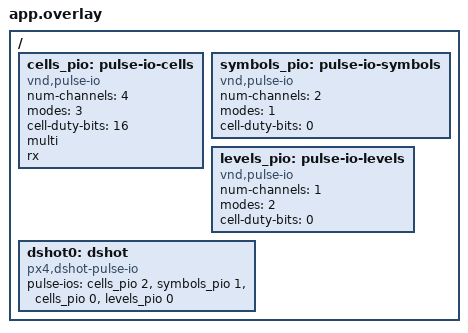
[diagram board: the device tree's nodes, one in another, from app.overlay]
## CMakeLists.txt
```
############################################################################
#
#   Copyright (c) 2026 PX4 Development Team. All rights reserved.
#
# Redistribution and use in source and binary forms, with or without
# modification, are permitted provided that the following conditions
# are met:
#
# 1. Redistributions of source code must retain the above copyright
#    notice, this list of conditions and the following disclaimer.
# 2. Redistributions in binary form must reproduce the above copyright
#    notice, this list of conditions and the following disclaimer in
#    the documentation and/or other materials provided with the
#    distribution.
# 3. Neither the name PX4 nor the names of its contributors may be
#    used to endorse or promote products derived from this software
#    without specific prior written permission.
#
# THIS SOFTWARE IS PROVIDED BY THE COPYRIGHT HOLDERS AND CONTRIBUTORS
# "AS IS" AND ANY EXPRESS OR IMPLIED WARRANTIES, INCLUDING, BUT NOT
# LIMITED TO, THE IMPLIED WARRANTIES OF MERCHANTABILITY AND FITNESS
# FOR A PARTICULAR PURPOSE ARE DISCLAIMED. IN NO EVENT SHALL THE
# COPYRIGHT OWNER OR CONTRIBUTORS BE LIABLE FOR ANY DIRECT, INDIRECT,
# INCIDENTAL, SPECIAL, EXEMPLARY, OR CONSEQUENTIAL DAMAGES (INCLUDING,
# BUT NOT LIMITED TO, PROCUREMENT OF SUBSTITUTE GOODS OR SERVICES; LOSS
# OF USE, DATA, OR PROFITS; OR BUSINESS INTERRUPTION) HOWEVER CAUSED
# AND ON ANY THEORY OF LIABILITY, WHETHER IN CONTRACT, STRICT
# LIABILITY, OR TORT (INCLUDING NEGLIGENCE OR OTHERWISE) ARISING IN
# ANY WAY OUT OF THE USE OF THIS SOFTWARE, EVEN IF ADVISED OF THE
# POSSIBILITY OF SUCH DAMAGE.
#
############################################################################

cmake_minimum_required(VERSION 3.20.0)

find_package(Zephyr REQUIRED HINTS $ENV{ZEPHYR_BASE})
project(px4_dshot_pulse_io_test)

target_sources(app PRIVATE
	src/fake_pulse_io.c
	src/main.c
)
```

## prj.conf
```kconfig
CONFIG_ZTEST=y
CONFIG_PX4=y
```

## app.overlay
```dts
/ {
	/* cells with a duty cycle, whose channels start together, as an STM32 timer */
	cells_pio: pulse-io-cells {
		compatible = "vnd,pulse-io";
		#pulse-io-cells = <1>;
		num-channels = <4>;
		modes = <3>;
		cell-duty-bits = <16>;
		multi;
		rx;
	};

	/* symbols only, as the RMT of the ESP32 */
	symbols_pio: pulse-io-symbols {
		compatible = "vnd,pulse-io";
		#pulse-io-cells = <1>;
		num-channels = <2>;
		modes = <1>;
		cell-duty-bits = <0>;
	};

	/* cells without a duty cycle, which can't send DShot */
	levels_pio: pulse-io-levels {
		compatible = "vnd,pulse-io";
		#pulse-io-cells = <1>;
		num-channels = <1>;
		modes = <2>;
		cell-duty-bits = <0>;
	};

	/* channels in another order than those of the controllers */
	dshot0: dshot {
		compatible = "px4,dshot-pulse-io";
		#dshot-cells = <1>;
		pulse-ios = <&cells_pio 2>, <&symbols_pio 1>, <&cells_pio 0>, <&levels_pio 0>;
	};
};
```

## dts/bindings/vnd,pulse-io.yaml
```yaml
description: |
  pulse_io controller of the PX4 DShot pulse_io test, which records the
  configuration of its channels and what they send

compatible: "vnd,pulse-io"

include: pulse-io-controller.yaml

properties:
  num-channels:
    type: int
    required: true
  modes:
    type: int
    required: true
    description: pulse_io_mode bitmask of the capabilities
  cell-duty-bits:
    type: int
    required: true
  multi:
    type: boolean
    description: the channels can start together (tx_sync_multi_channel)
  rx:
    type: boolean
    description: the channels receive the reply set by the test after a transmit, through RTIO
```

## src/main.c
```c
/****************************************************************************
 *
 *   Copyright (c) 2026 PX4 Development Team. All rights reserved.
 *
 * Redistribution and use in source and binary forms, with or without
 * modification, are permitted provided that the following conditions
 * are met:
 *
 * 1. Redistributions of source code must retain the above copyright
 *    notice, this list of conditions and the following disclaimer.
 * 2. Redistributions in binary form must reproduce the above copyright
 *    notice, this list of conditions and the following disclaimer in
 *    the documentation and/or other materials provided with the
 *    distribution.
 * 3. Neither the name PX4 nor the names of its contributors may be
 *    used to endorse or promote products derived from this software
 *    without specific prior written permission.
 *
 * THIS SOFTWARE IS PROVIDED BY THE COPYRIGHT HOLDERS AND CONTRIBUTORS
 * "AS IS" AND ANY EXPRESS OR IMPLIED WARRANTIES, INCLUDING, BUT NOT
 * LIMITED TO, THE IMPLIED WARRANTIES OF MERCHANTABILITY AND FITNESS
 * FOR A PARTICULAR PURPOSE ARE DISCLAIMED. IN NO EVENT SHALL THE
 * COPYRIGHT OWNER OR CONTRIBUTORS BE LIABLE FOR ANY DIRECT, INDIRECT,
 * INCIDENTAL, SPECIAL, EXEMPLARY, OR CONSEQUENTIAL DAMAGES (INCLUDING,
 * BUT NOT LIMITED TO, PROCUREMENT OF SUBSTITUTE GOODS OR SERVICES; LOSS
 * OF USE, DATA, OR PROFITS; OR BUSINESS INTERRUPTION) HOWEVER CAUSED
 * AND ON ANY THEORY OF LIABILITY, WHETHER IN CONTRACT, STRICT
 * LIABILITY, OR TORT (INCLUDING NEGLIGENCE OR OTHERWISE) ARISING IN
 * ANY WAY OUT OF THE USE OF THIS SOFTWARE, EVEN IF ADVISED OF THE
 * POSSIBILITY OF SUCH DAMAGE.
 *
 ****************************************************************************/

/*
 * DShot device on pulse_io channels (px4,dshot-pulse-io), on pulse_io controllers of the test: the
 * configuration of the channels for each bit rate, the cells and symbols of the frames, the channels of a
 * controller that start together and the others, the inverted frames of bidirectional channels and the
 * replies received after them, and the errors.
 */

#include "fake_pulse_io.h"

#include <px4_dshot.h>

#include <errno.h>

#include <zephyr/device.h>
#include <zephyr/ztest.h>

static const struct device *const dshot = DEVICE_DT_GET(DT_NODELABEL(dshot0));
static const struct device *const cells_pio = DEVICE_DT_GET(DT_NODELABEL(cells_pio));
static const struct device *const symbols_pio = DEVICE_DT_GET(DT_NODELABEL(symbols_pio));
static const struct device *const levels_pio = DEVICE_DT_GET(DT_NODELABEL(levels_pio));

/* the pulse_io channels of the DShot channels, see app.overlay */
#define CH0 fake_pio_channel(cells_pio, 2)
#define CH1 fake_pio_channel(symbols_pio, 1)
#define CH2 fake_pio_channel(cells_pio, 0)
#define CH3 fake_pio_channel(levels_pio, 0)

/* ticks of a bit, high time of a 1 and of a 0 */
#define BIT_TICKS  40
#define ONE_TICKS  30
#define ZERO_TICKS 15

static void reset(void *fixture)
{
	ARG_UNUSED(fixture);

	zassert_ok(px4_dshot_configure(dshot, 0, 0, 600000));
	fake_pio_clear();
}

ZTEST_SUITE(dshot_pulse_io, NULL, NULL, reset, NULL, NULL);

static void check_channel_config(const struct fake_pio_channel *ch, enum pulse_io_mode mode, uint32_t bit_rate)
{
	zassert_true(ch->reserved);
	zassert_true(ch->configured);
	zassert_equal(ch->cfg.mode, mode);
	zassert_equal(ch->cfg.dir, PULSE_IO_DIR_TX);
	zassert_equal(ch->cfg.resolution_hz, bit_rate * BIT_TICKS);
	zassert_false(ch->cfg.idle_high);

	if (mode == PULSE_IO_MODE_CELL) {
		zassert_equal(ch->cfg.cell_period_ticks, BIT_TICKS);
	}
}

ZTEST(dshot_pulse_io, test_configure)
{
	zassert_ok(px4_dshot_configure(dshot, BIT(0) | BIT(1) | BIT(2), 0, 600000));

	check_channel_config(CH0, PULSE_IO_MODE_CELL, 600000);
	check_channel_config(CH1, PULSE_IO_MODE_SYMBOL, 600000);
	check_channel_config(CH2, PULSE_IO_MODE_CELL, 600000);

	/* the channels that aren't DShot channels, or aren't configured, are left alone */
	zassert_false(fake_pio_channel(cells_pio, 1)->reserved);
	zassert_false(fake_pio_channel(cells_pio, 3)->reserved);
	zassert_false(fake_pio_channel(symbols_pio, 0)->reserved);
	zassert_false(CH3->reserved);
}

ZTEST(dshot_pulse_io, test_bit_rates)
{
	zassert_ok(px4_dshot_configure(dshot, BIT(0) | BIT(1), 0, 150000));
	check_channel_config(CH0, PULSE_IO_MODE_CELL, 150000);
	check_channel_config(CH1, PULSE_IO_MODE_SYMBOL, 150000);

	zassert_ok(px4_dshot_configure(dshot, BIT(0) | BIT(1), 0, 300000));
	check_channel_config(CH0, PULSE_IO_MODE_CELL, 300000);
	check_channel_config(CH1, PULSE_IO_MODE_SYMBOL, 300000);
}

ZTEST(dshot_pulse_io, test_reconfigure)
{
	zassert_ok(px4_dshot_configure(dshot, BIT(0) | BIT(2), 0, 600000));

	/* in place of the previous configuration */
	zassert_ok(px4_dshot_configure(dshot, BIT(0), 0, 600000));
	check_channel_config(CH0, PULSE_IO_MODE_CELL, 600000);
	zassert_false(CH2->reserved);

	zassert_equal(px4_dshot_send(dshot, BIT(2), (const uint16_t[3]) {0}), -EINVAL);
	zassert_equal(CH2->transmits, 0);
}

ZTEST(dshot_pulse_io, test_configure_errors)
{
	zassert_ok(px4_dshot_configure(dshot, BIT(0), 0, 600000));

	/* a bidirectional channel on a controller that doesn't receive */
	zassert_equal(px4_dshot_configure(dshot, BIT(1), BIT(1), 600000), -EINVAL);
	zassert_ok(px4_dshot_configure(dshot, BIT(0), 0, 600000));

	zassert_equal(px4_dshot_configure(dshot, BIT(0), 0, 400000), -EINVAL);
	zassert_equal(px4_dshot_configure(dshot, BIT(4), 0, 600000), -EINVAL);

	/* cells without a duty cycle, which leaves no channel configured */
	zassert_ok(px4_dshot_configure(dshot, BIT(0), 0, 600000));
	zassert_equal(px4_dshot_configure(dshot, BIT(0) | BIT(3), 0, 600000), -EINVAL);
	zassert_false(CH0->reserved);
	zassert_false(CH3->reserved);
	zassert_equal(px4_dshot_send(dshot, BIT(0), (const uint16_t[1]) {0}), -EINVAL);
}

ZTEST(dshot_pulse_io, test_frames)
{
	/* bits 1010 0101 1100 0011, the most significant first */
	const uint16_t frame = 0xa5c3;
	const uint16_t frames[3] = {frame, frame, frame};

	zassert_ok(px4_dshot_configure(dshot, BIT(0) | BIT(1) | BIT(2), 0, 600000));
	zassert_ok(px4_dshot_send(dshot, BIT(0) | BIT(1) | BIT(2), frames));

	/* 16 cells and an idle cell */
	for (int c = 0; c < 2; c++) {
		const struct fake_pio_channel *ch = (c == 0) ? CH0 : CH2;

		zassert_equal(ch->transmits, 1);
		zassert_equal(ch->count, 17);

		for (int i = 0; i < 16; i++) {
			const bool one = (frame & BIT(15 - i)) != 0;

			zassert_equal(ch->cells[i].duty, one ? ONE_TICKS : ZERO_TICKS, "cell %d", i);
		}

		zassert_equal(ch->cells[16].duty, 0);
	}

	/* a high and a low symbol for each bit */
	zassert_equal(CH1->transmits, 1);
	zassert_equal(CH1->count, 32);

	for (int i = 0; i < 16; i++) {
		const bool one = (frame & BIT(15 - i)) != 0;

		zassert_equal(CH1->symbols[2 * i].level, 1);
		zassert_equal(CH1->symbols[2 * i].duration, one ? ONE_TICKS : ZERO_TICKS, "bit %d", i);
		zassert_equal(CH1->symbols[2 * i + 1].level, 0);
		zassert_equal(CH1->symbols[2 * i + 1].duration, one ? BIT_TICKS - ONE_TICKS : BIT_TICKS - ZERO_TICKS);
	}
}

ZTEST(dshot_pulse_io, test_channels)
{
	const uint16_t frames[3] = {0x0001, 0x0002, 0x0004};

	zassert_ok(px4_dshot_configure(dshot, BIT(0) | BIT(1) | BIT(2), 0, 600000));

	/* the given channels, each with its frame, which start together on the same controller */
	zassert_ok(px4_dshot_send(dshot, BIT(0) | BIT(2), frames));
	zassert_equal(CH0->transmits, 1);
	zassert_equal(CH1->transmits, 0);
	zassert_equal(CH2->transmits, 1);
	zassert_equal(CH0->cells[15].duty, ONE_TICKS);
	zassert_equal(CH2->cells[13].duty, ONE_TICKS);
	zassert_equal(CH2->cells[15].duty, ZERO_TICKS);
	zassert_true(CH0->multi);
	zassert_true(CH2->multi);
	zassert_equal(CH0->sequence, CH2->sequence);

	/* the channel of the other controller after them */
	zassert_ok(px4_dshot_send(dshot, BIT(0) | BIT(1) | BIT(2), frames));
	zassert_equal(CH0->sequence, CH2->sequence);
	zassert_true(CH0->sequence < CH1->sequence);
	zassert_false(CH1->multi);

	/* a single channel of a controller */
	zassert_ok(px4_dshot_send(dshot, BIT(2), frames));
	zassert_false(CH2->multi);
	zassert_equal(CH2->transmits, 3);
}

ZTEST(dshot_pulse_io, test_transmit_error)
{
	const uint16_t frames[3] = {0};

	zassert_ok(px4_dshot_configure(dshot, BIT(0) | BIT(1) | BIT(2), 0, 600000));

	/* the other channels still send */
	CH1->transmit_error = -EIO;
	zassert_equal(px4_dshot_send(dshot, BIT(0) | BIT(1) | BIT(2), frames), -EIO);
	zassert_equal(CH0->transmits, 1);
	zassert_equal(CH2->transmits, 1);

	/* also those that start together with the failing one */
	CH1->transmit_error = 0;
	CH2->transmit_error = -EIO;
	zassert_equal(px4_dshot_send(dshot, BIT(0) | BIT(1) | BIT(2), frames), -EIO);
	zassert_equal(CH0->transmits, 2);
	zassert_equal(CH1->transmits, 1);
}

ZTEST(dshot_pulse_io, test_no_reply)
{
	uint32_t reply;

	zassert_ok(px4_dshot_configure(dshot, BIT(0), 0, 600000));
	zassert_ok(px4_dshot_send(dshot, BIT(0), (const uint16_t[1]) {0}));
	zassert_equal(px4_dshot_get_reply(dshot, 0, &reply), -ENODATA);
}

/* ticks of a bit of the reply, at 5/4 of the bit rate */
#define REPLY_BIT_TICKS 32

/* the symbols of a reply 30 us after the frame: the start bit, then 20 bits as line levels, the first in bit 19 */
static size_t make_reply(struct pulse_symbol *symbols, uint32_t bits)
{
	size_t n = 0;

	symbols[n++] = (struct pulse_symbol) {.duration = 720, .level = 1};
	symbols[n++] = (struct pulse_symbol) {.duration = REPLY_BIT_TICKS, .level = 0};

	for (int i = 19; i >= 0; i--) {
		const uint32_t level = (bits >> i) & 1;

		if (symbols[n - 1].level == level) {
			symbols[n - 1].duration += REPLY_BIT_TICKS;

		} else {
			symbols[n++] = (struct pulse_symbol) {.duration = REPLY_BIT_TICKS, .level = level};
		}
	}

	/* the line idles high after the reply */
	if (symbols[n - 1].level == 1) {
		symbols[n - 1].duration += 1440;

	} else {
		symbols[n++] = (struct pulse_symbol) {.duration = 1440, .level = 1};
	}

	return n;
}

ZTEST(dshot_pulse_io, test_bidirectional_configure)
{
	zassert_ok(px4_dshot_configure(dshot, BIT(0) | BIT(2), BIT(0), 600000));

	/* half duplex, idling high, with a receive that ends 60 us after the last edge */
	zassert_equal(CH0->cfg.dir, PULSE_IO_DIR_TX_RX);
	zassert_true(CH0->cfg.idle_high);
	zassert_equal(CH0->cfg.rx_idle_threshold_ticks, 24 * 60);
	zassert_equal(CH2->cfg.dir, PULSE_IO_DIR_TX);
	zassert_false(CH2->cfg.idle_high);

	/* the line rests low for the 20 ms that take an AM32 ESC out of its bootloader before it idles high */
	zassert_true(CH0->low_before_high_ms >= 20, "low for %lld ms", CH0->low_before_high_ms);

	/* a controller that doesn't receive, and a bidirectional channel that isn't configured */
	zassert_equal(px4_dshot_configure(dshot, BIT(1), BIT(1), 600000), -EINVAL);
	zassert_equal(px4_dshot_configure(dshot, BIT(0), BIT(2), 600000), -EINVAL);
}

ZTEST(dshot_pulse_io, test_bidirectional_frame)
{
	/* bits 1010 0101 1100 0011 */
	const uint16_t frame = 0xa5c3;
	uint32_t reply;

	zassert_equal(px4_dshot_get_reply(dshot, 0, &reply), -ENODATA);

	zassert_ok(px4_dshot_configure(dshot, BIT(0), BIT(0), 600000));
	zassert_ok(px4_dshot_send(dshot, BIT(0), &frame));

	/* inverted: the line is low for 3/4 of a 1 and 3/8 of a 0, then idles high, sent without the others */
	zassert_equal(CH0->transmits, 1);
	zassert_false(CH0->multi);
	zassert_equal(CH0->count, 17);

	for (int i = 0; i < 16; i++) {
		const bool one = (frame & BIT(15 - i)) != 0;

		zassert_equal(CH0->cells[i].duty, one ? BIT_TICKS - ONE_TICKS : BIT_TICKS - ZERO_TICKS, "cell %d", i);
	}

	zassert_equal(CH0->cells[16].duty, BIT_TICKS);

	/* the line stays high: no reply */
	zassert_equal(CH0->receives, 1);
	zassert_equal(px4_dshot_get_reply(dshot, 0, &reply), -ENODATA);
}

ZTEST(dshot_pulse_io, test_bidirectional_reply)
{
	const uint32_t bits[] = {0xa5c3f, 0x00001, 0xfffff, 0x55555};
	uint32_t reply;

	zassert_ok(px4_dshot_configure(dshot, BIT(0) | BIT(2), BIT(0) | BIT(2), 600000));

	for (size_t i = 0; i < ARRAY_SIZE(bits); i++) {
		CH0->reply_count = make_reply(CH0->reply, bits[i]);
		CH2->reply_count = make_reply(CH2->reply, bits[i] ^ 0xfffff);

		zassert_ok(px4_dshot_send(dshot, BIT(0) | BIT(2), (const uint16_t[3]) {0}));

		zassert_ok(px4_dshot_get_reply(dshot, 0, &reply));
		zassert_equal(reply, bits[i], "reply 0x%05x instead of 0x%05x", reply, bits[i]);
		zassert_ok(px4_dshot_get_reply(dshot, 2, &reply));
		zassert_equal(reply, bits[i] ^ 0xfffff);

		/* returned once */
		zassert_equal(px4_dshot_get_reply(dshot, 0, &reply), -ENODATA);
	}
}
```

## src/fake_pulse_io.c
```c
/****************************************************************************
 *
 *   Copyright (c) 2026 PX4 Development Team. All rights reserved.
 *
 * Redistribution and use in source and binary forms, with or without
 * modification, are permitted provided that the following conditions
 * are met:
 *
 * 1. Redistributions of source code must retain the above copyright
 *    notice, this list of conditions and the following disclaimer.
 * 2. Redistributions in binary form must reproduce the above copyright
 *    notice, this list of conditions and the following disclaimer in
 *    the documentation and/or other materials provided with the
 *    distribution.
 * 3. Neither the name PX4 nor the names of its contributors may be
 *    used to endorse or promote products derived from this software
 *    without specific prior written permission.
 *
 * THIS SOFTWARE IS PROVIDED BY THE COPYRIGHT HOLDERS AND CONTRIBUTORS
 * "AS IS" AND ANY EXPRESS OR IMPLIED WARRANTIES, INCLUDING, BUT NOT
 * LIMITED TO, THE IMPLIED WARRANTIES OF MERCHANTABILITY AND FITNESS
 * FOR A PARTICULAR PURPOSE ARE DISCLAIMED. IN NO EVENT SHALL THE
 * COPYRIGHT OWNER OR CONTRIBUTORS BE LIABLE FOR ANY DIRECT, INDIRECT,
 * INCIDENTAL, SPECIAL, EXEMPLARY, OR CONSEQUENTIAL DAMAGES (INCLUDING,
 * BUT NOT LIMITED TO, PROCUREMENT OF SUBSTITUTE GOODS OR SERVICES; LOSS
 * OF USE, DATA, OR PROFITS; OR BUSINESS INTERRUPTION) HOWEVER CAUSED
 * AND ON ANY THEORY OF LIABILITY, WHETHER IN CONTRACT, STRICT
 * LIABILITY, OR TORT (INCLUDING NEGLIGENCE OR OTHERWISE) ARISING IN
 * ANY WAY OUT OF THE USE OF THIS SOFTWARE, EVEN IF ADVISED OF THE
 * POSSIBILITY OF SUCH DAMAGE.
 *
 ****************************************************************************/

/*
 * pulse_io controller of the test, with the capabilities of its devicetree node, which records the
 * configuration of its channels and the last frame each sent
 */

#define DT_DRV_COMPAT vnd_pulse_io

#include "fake_pulse_io.h"

#include <errno.h>
#include <string.h>

#include <zephyr/kernel.h>
#include <zephyr/rtio/rtio.h>
#include <zephyr/sys/util.h>

struct fake_pio_config {
	uint8_t num_channels;
	uint32_t modes;
	uint8_t cell_duty_bits;
	bool multi;
	bool rx;
};

struct fake_pio_data {
	struct fake_pio_channel channels[FAKE_PIO_MAX_CHANNELS];
};

static uint32_t sequence;

static struct fake_pio_channel *get_channel(const struct device *dev, struct pulse_io_channel *chan)
{
	const struct fake_pio_config *cfg = dev->config;
	struct fake_pio_data *data = dev->data;
	const uintptr_t idx = (uintptr_t)chan - 1U;

	if ((idx >= cfg->num_channels) || !data->channels[idx].reserved) {
		return NULL;
	}

	return &data->channels[idx];
}

static int fake_pio_get_capabilities(const struct device *dev, struct pulse_io_caps *caps)
{
	const struct fake_pio_config *cfg = dev->config;

	*caps = (struct pulse_io_caps) {
		.tx_max_streaming = FAKE_PIO_MAX_ENTRIES,
		.modes = cfg->modes,
		.min_tick_ns = 1,
		.max_tick_ns = 1000000,
		.max_duration_ticks = UINT16_MAX,
		.tx_channel_mask = BIT_MASK(cfg->num_channels),
		.cell_duty_bits = cfg->cell_duty_bits,
		.num_channels = cfg->num_channels,
		.supports_tx = true,
		.supports_rx = cfg->rx,
		.rx_channel_mask = cfg->rx ? BIT_MASK(cfg->num_channels) : 0,
		.tx_sync_multi_channel = cfg->multi,
	};

	return 0;
}

static int fake_pio_channel_get(const struct device *dev, uint8_t channel_idx, struct pulse_io_channel **chan)
{
	const struct fake_pio_config *cfg = dev->config;
	struct fake_pio_data *data = dev->data;

	if (channel_idx >= cfg->num_channels) {
		return -ENODEV;
	}

	if (data->channels[channel_idx].reserved) {
		return -EBUSY;
	}

	data->channels[channel_idx].reserved = true;
	*chan = (struct pulse_io_channel *)(uintptr_t)(channel_idx + 1U);

	return 0;
}

static int fake_pio_channel_release(const struct device *dev, struct pulse_io_channel *chan)
{
	struct fake_pio_channel *ch = get_channel(dev, chan);

	if (ch == NULL) {
		return -EINVAL;
	}

	ch->reserved = false;
	ch->configured = false;
	ch->low_since_ms = 0;

	return 0;
}

static int fake_pio_channel_configure(const struct device *dev, struct pulse_io_channel *chan,
				      const struct pulse_io_config *pio_cfg)
{
	const struct fake_pio_config *cfg = dev->config;
	struct fake_pio_channel *ch = get_channel(dev, chan);

	if (ch == NULL) {
		return -EINVAL;
	}

	if (((pio_cfg->mode & cfg->modes) == 0) ||
	    ((pio_cfg->dir != PULSE_IO_DIR_TX) && ((pio_cfg->dir != PULSE_IO_DIR_TX_RX) || !cfg->rx))) {
		return -ENOTSUP;
	}

	ch->cfg = *pio_cfg;
	ch->configured = true;

	if (!pio_cfg->idle_high) {
		ch->low_since_ms = (ch->low_since_ms != 0) ? ch->low_since_ms : k_uptime_get();

	} else {
		ch->low_before_high_ms = (ch->low_since_ms != 0) ? k_uptime_get() - ch->low_since_ms : 0;
		ch->low_since_ms = 0;
	}

	return 0;
}

static int transmit(struct fake_pio_channel *ch, const struct pulse_io_tx_req *req, uint32_t seq, bool multi)
{
	ch->sequence = seq;
	ch->multi = multi;

	if (ch->transmit_error != 0) {
		return ch->transmit_error;
	}

	if (ch->cfg.mode == PULSE_IO_MODE_CELL) {
		memcpy(ch->cells, req->cells, req->count * sizeof(req->cells[0]));

	} else {
		memcpy(ch->symbols, req->symbols, req->count * sizeof(req->symbols[0]));
	}

	ch->count = req->count;
	ch->transmits++;

	return 0;
}

static int fake_pio_transmit_sync(const struct device *dev, struct pulse_io_channel *chan,
				  const struct pulse_io_tx_req *req, k_timeout_t timeout)
{
	struct fake_pio_channel *ch = get_channel(dev, chan);

	ARG_UNUSED(timeout);

	if ((ch == NULL) || !ch->configured) {
		return -EINVAL;
	}

	if (req->count > FAKE_PIO_MAX_ENTRIES) {
		return -ENOMEM;
	}

	return transmit(ch, req, ++sequence, false);
}

static int fake_pio_transmit_multi_sync(const struct device *dev, struct pulse_io_channel *const *chans,
					const struct pulse_io_tx_req *reqs, size_t num, k_timeout_t timeout)
{
	const struct fake_pio_config *cfg = dev->config;
	int ret = 0;

	ARG_UNUSED(timeout);

	if (!cfg->multi) {
		return -ENOSYS;
	}

	for (size_t i = 0; i < num; i++) {
		struct fake_pio_channel *ch = get_channel(dev, chans[i]);

		if ((ch == NULL) || !ch->configured) {
			return -EINVAL;
		}

		for (size_t j = 0; j < i; j++) {
			if (chans[j] == chans[i]) {
				return -EINVAL;
			}
		}

		if (reqs[i].count > FAKE_PIO_MAX_ENTRIES) {
			return -ENOMEM;
		}
	}

	/* the channels start together: one sequence number for all */
	sequence++;

	for (size_t i = 0; i < num; i++) {
		const int err = transmit(get_channel(dev, chans[i]), &reqs[i], sequence, true);

		if ((err < 0) && (ret == 0)) {
			ret = err;
		}
	}

	return ret;
}

static int fake_pio_receive_sync(const struct device *dev, struct pulse_io_channel *chan,
				 const struct pulse_io_rx_req *req, size_t *count, k_timeout_t timeout)
{
	return -ENOTSUP;
}

static int fake_pio_stop(const struct device *dev, struct pulse_io_channel *chan)
{
	return 0;
}

static void fake_pio_submit(const struct device *dev, struct rtio_iodev_sqe *iodev_sqe)
{
	const struct fake_pio_config *cfg = dev->config;
	struct fake_pio_channel *ch = get_channel(dev, pulse_io_iodev_channel(iodev_sqe));
	const struct rtio_sqe *sqe = &iodev_sqe->sqe;

	if ((ch == NULL) || !ch->configured) {
		rtio_iodev_sqe_err(iodev_sqe, -EINVAL);
		return;
	}

	if (sqe->op == RTIO_OP_TX) {
		const struct pulse_io_tx_req req = {
			.symbols = (const struct pulse_symbol *)sqe->tx.buf,
			.count = sqe->tx.buf_len / sizeof(struct pulse_symbol),
		};

		if (req.count > FAKE_PIO_MAX_ENTRIES) {
			rtio_iodev_sqe_err(iodev_sqe, -ENOMEM);
			return;
		}

		const int ret = transmit(ch, &req, ++sequence, false);

		if (ret < 0) {
			rtio_iodev_sqe_err(iodev_sqe, ret);

		} else {
			rtio_iodev_sqe_ok(iodev_sqe, 0);
		}

		return;
	}

	if ((sqe->op != RTIO_OP_RX) || !cfg->rx || (ch->cfg.dir != PULSE_IO_DIR_TX_RX)) {
		rtio_iodev_sqe_err(iodev_sqe, -ENOTSUP);
		return;
	}

	/* without a reply, the line stays at its idle level */
	const struct pulse_symbol idle = {.duration = ch->cfg.rx_idle_threshold_ticks, .level = 1};
	const struct pulse_symbol *reply = (ch->reply_count > 0) ? ch->reply : &idle;
	const size_t count = MAX(ch->reply_count, 1);
	uint8_t *buf;
	uint32_t buf_len;
	const int ret = rtio_sqe_rx_buf(iodev_sqe, count * sizeof(reply[0]), count * sizeof(reply[0]), &buf, &buf_len);

	if (ret < 0) {
		rtio_iodev_sqe_err(iodev_sqe, ret);
		return;
	}

	memcpy(buf, reply, count * sizeof(reply[0]));
	ch->receives++;
	rtio_iodev_sqe_ok(iodev_sqe, count * sizeof(reply[0]));
}

static DEVICE_API(pulse_io, fake_pio_api) = {
	.get_capabilities = fake_pio_get_capabilities,
	.channel_get = fake_pio_channel_get,
	.channel_release = fake_pio_channel_release,
	.channel_configure = fake_pio_channel_configure,
	.transmit_sync = fake_pio_transmit_sync,
	.receive_sync = fake_pio_receive_sync,
	.stop = fake_pio_stop,
	.transmit_multi_sync = fake_pio_transmit_multi_sync,
	.submit = fake_pio_submit,
};

#define FAKE_PIO_DEFINE(inst)                                                                                  \
	BUILD_ASSERT(DT_INST_PROP(inst, num_channels) <= FAKE_PIO_MAX_CHANNELS);                              \
	static const struct fake_pio_config fake_pio_config_##inst = {                                         \
		.num_channels = DT_INST_PROP(inst, num_channels),                                              \
		.modes = DT_INST_PROP(inst, modes),                                                            \
		.cell_duty_bits = DT_INST_PROP(inst, cell_duty_bits),                                          \
		.multi = DT_INST_PROP(inst, multi),                                                            \
		.rx = DT_INST_PROP(inst, rx),                                                                  \
	};                                                                                                     \
	static struct fake_pio_data fake_pio_data_##inst;                                                      \
	DEVICE_DT_INST_DEFINE(inst, NULL, NULL, &fake_pio_data_##inst, &fake_pio_config_##inst, POST_KERNEL,   \
			      CONFIG_PULSE_IO_INIT_PRIORITY, &fake_pio_api);

DT_INST_FOREACH_STATUS_OKAY(FAKE_PIO_DEFINE)

#define FAKE_PIO_DATA(inst) &fake_pio_data_##inst,

static struct fake_pio_data *const all_data[] = {DT_INST_FOREACH_STATUS_OKAY(FAKE_PIO_DATA)};

void fake_pio_clear(void)
{
	for (size_t i = 0; i < ARRAY_SIZE(all_data); i++) {
		for (size_t c = 0; c < FAKE_PIO_MAX_CHANNELS; c++) {
			struct fake_pio_channel *ch = &all_data[i]->channels[c];

			ch->count = 0;
			ch->transmits = 0;
			ch->sequence = 0;
			ch->multi = false;
			ch->transmit_error = 0;
			ch->reply_count = 0;
			ch->receives = 0;
		}
	}
}

struct fake_pio_channel *fake_pio_channel(const struct device *dev, uint8_t channel)
{
	struct fake_pio_data *data = dev->data;

	__ASSERT_NO_MSG(channel < FAKE_PIO_MAX_CHANNELS);

	return &data->channels[channel];
}
```

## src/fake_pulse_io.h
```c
/****************************************************************************
 *
 *   Copyright (c) 2026 PX4 Development Team. All rights reserved.
 *
 * Redistribution and use in source and binary forms, with or without
 * modification, are permitted provided that the following conditions
 * are met:
 *
 * 1. Redistributions of source code must retain the above copyright
 *    notice, this list of conditions and the following disclaimer.
 * 2. Redistributions in binary form must reproduce the above copyright
 *    notice, this list of conditions and the following disclaimer in
 *    the documentation and/or other materials provided with the
 *    distribution.
 * 3. Neither the name PX4 nor the names of its contributors may be
 *    used to endorse or promote products derived from this software
 *    without specific prior written permission.
 *
 * THIS SOFTWARE IS PROVIDED BY THE COPYRIGHT HOLDERS AND CONTRIBUTORS
 * "AS IS" AND ANY EXPRESS OR IMPLIED WARRANTIES, INCLUDING, BUT NOT
 * LIMITED TO, THE IMPLIED WARRANTIES OF MERCHANTABILITY AND FITNESS
 * FOR A PARTICULAR PURPOSE ARE DISCLAIMED. IN NO EVENT SHALL THE
 * COPYRIGHT OWNER OR CONTRIBUTORS BE LIABLE FOR ANY DIRECT, INDIRECT,
 * INCIDENTAL, SPECIAL, EXEMPLARY, OR CONSEQUENTIAL DAMAGES (INCLUDING,
 * BUT NOT LIMITED TO, PROCUREMENT OF SUBSTITUTE GOODS OR SERVICES; LOSS
 * OF USE, DATA, OR PROFITS; OR BUSINESS INTERRUPTION) HOWEVER CAUSED
 * AND ON ANY THEORY OF LIABILITY, WHETHER IN CONTRACT, STRICT
 * LIABILITY, OR TORT (INCLUDING NEGLIGENCE OR OTHERWISE) ARISING IN
 * ANY WAY OUT OF THE USE OF THIS SOFTWARE, EVEN IF ADVISED OF THE
 * POSSIBILITY OF SUCH DAMAGE.
 *
 ****************************************************************************/

/*
 * pulse_io controller that records the configuration of its channels and the last frame each sent, with the
 * order in which the channels sent
 */

#pragma once

#include <stdbool.h>
#include <stddef.h>
#include <stdint.h>

#include <zephyr/device.h>
#include <zephyr/drivers/pulse_io.h>

#define FAKE_PIO_MAX_CHANNELS 4
#define FAKE_PIO_MAX_ENTRIES  40

struct fake_pio_channel {
	bool reserved;
	bool configured;
	struct pulse_io_config cfg;
	/* uptime since which the line rests low, 0 while it doesn't, and how long it rested low before it last idled high */
	int64_t low_since_ms;
	int64_t low_before_high_ms;
	/* the last transmit: cells or symbols, as configured */
	size_t count;
	struct pulse_cell cells[FAKE_PIO_MAX_ENTRIES];
	struct pulse_symbol symbols[FAKE_PIO_MAX_ENTRIES];
	uint32_t transmits;
	/* sequence number of the last transmit, across the controllers, the same for the channels that start together */
	uint32_t sequence;
	/* the last transmit started together with other channels */
	bool multi;
	/* error of the next transmits, 0 to send */
	int transmit_error;
	/* the reply received after each transmit through RTIO, the line idling high without one */
	struct pulse_symbol reply[FAKE_PIO_MAX_ENTRIES];
	size_t reply_count;
	uint32_t receives;
};

/* reset the recordings, keeping the reservations and configurations */
void fake_pio_clear(void);

struct fake_pio_channel *fake_pio_channel(const struct device *dev, uint8_t channel);
```
